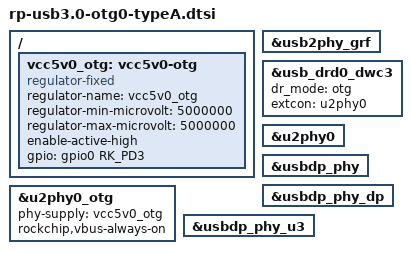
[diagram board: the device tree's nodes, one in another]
/{
    vcc5v0_otg: vcc5v0-otg {
        compatible = "regulator-fixed";
        regulator-name = "vcc5v0_otg";
        regulator-min-microvolt = <5000000>;
        regulator-max-microvolt = <5000000>;
        enable-active-high;
        gpio = <&gpio0 RK_PD3 GPIO_ACTIVE_HIGH>;
    };
};


&usb2phy_grf {
    status="okay";
};

&usb_drd0_dwc3 {
    status="okay";
    dr_mode = "otg";
    extcon = <&u2phy0>;
    // usb-role-switch; // This property is configurable only on Type-C interfaces.
};

&u2phy0_otg {
    status = "okay";
    phy-supply = <&vcc5v0_otg>;
    rockchip,vbus-always-on;
};

&u2phy0 {
    status = "okay";
};

&usbdp_phy {
    status = "okay";
};

&usbdp_phy_dp {
    status = "okay";
};

&usbdp_phy_u3 {
    status = "okay";
};
